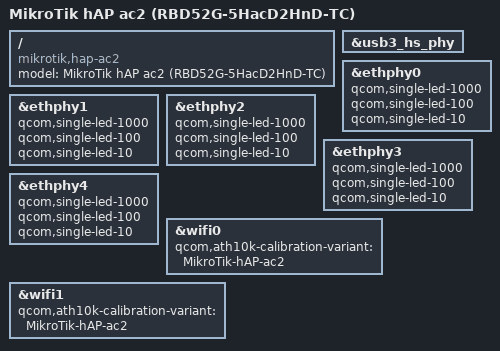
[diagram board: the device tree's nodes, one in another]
// SPDX-License-Identifier: GPL-2.0-or-later OR MIT
/* Copyright (c) 2020, Robert Marko <robimarko@gmail.com> */

#include "qcom-ipq4018-mikrotik-5acd.dtsi"

/ {
	model = "MikroTik hAP ac2 (RBD52G-5HacD2HnD-TC)";
	compatible = "mikrotik,hap-ac2";
};

&usb3_hs_phy {
	status = "okay";
};

&ethphy0 {
	qcom,single-led-1000;
	qcom,single-led-100;
	qcom,single-led-10;
};

&ethphy1 {
	qcom,single-led-1000;
	qcom,single-led-100;
	qcom,single-led-10;
};

&ethphy2 {
	qcom,single-led-1000;
	qcom,single-led-100;
	qcom,single-led-10;
};

&ethphy3 {
	qcom,single-led-1000;
	qcom,single-led-100;
	qcom,single-led-10;
};

&ethphy4 {
	qcom,single-led-1000;
	qcom,single-led-100;
	qcom,single-led-10;
};

&wifi0 {
	status = "okay";

	qcom,ath10k-calibration-variant = "MikroTik-hAP-ac2";
};

&wifi1 {
	status = "okay";

	qcom,ath10k-calibration-variant = "MikroTik-hAP-ac2";
};
